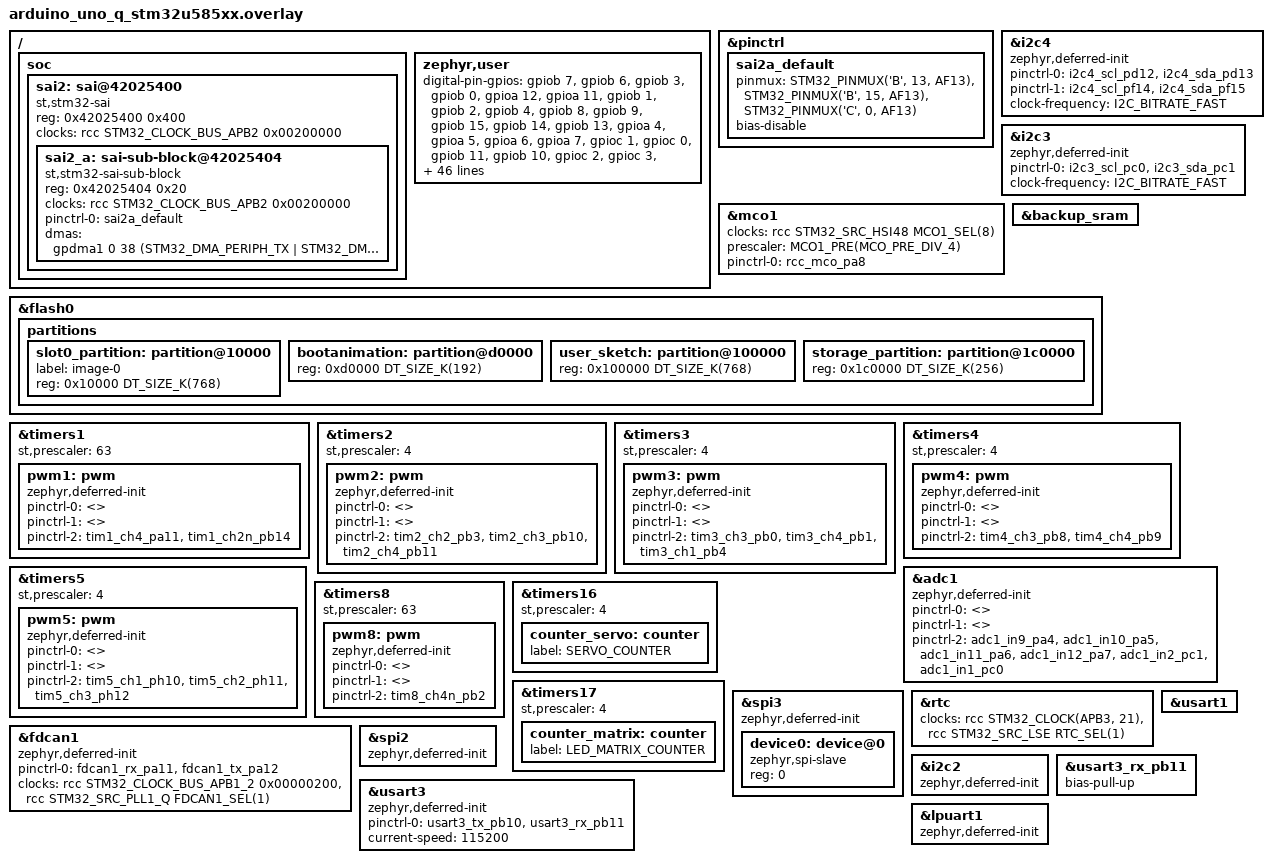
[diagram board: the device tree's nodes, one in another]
/*
 * Copyright (c) Arduino s.r.l. and/or its affiliated companies
 *
 * SPDX-License-Identifier: Apache-2.0
 */
#include <zephyr/dt-bindings/pwm/stm32_pwm.h>
#include <zephyr/dt-bindings/pinctrl/stm32-pinctrl.h>
#include <zephyr/dt-bindings/dma/stm32_dma.h>

/* Pinmux configuration for STM32U585 SAI2 Block A */
/*
 * BUG FIX (2026-08-21): the 'group1' sub-node below is Linux-devicetree
 * pinctrl convention (grouping multiple pin configs under named sub-groups
 * for things like open-drain-per-group vs push-pull-per-group). Confirmed
 * via a real CI compile failure that Zephyr's STM32 pinctrl binding
 * (dts/bindings/pinctrl/st,stm32-pinctrl.yaml, upstream
 * zephyrproject-rtos/zephyr) does NOT use that convention -- its
 * child-binding requires `pinmux` directly on the state node itself
 * (one level below &pinctrl), not nested inside an intermediate group.
 * Confirmed against every one of the 4260 real pin definitions in
 * hal_stm32's stm32u585aiix-pinctrl.dtsi (zephyrproject-rtos/hal_stm32):
 * zero use `group1`-style nesting anywhere; every single one sets pinmux
 * directly on its named leaf node (e.g. `sai2_sd_a_pb15 { pinmux = ...; };`).
 * The pin ASSIGNMENTS below were never wrong -- confirmed against that
 * same vendor file (sai2_sck_a_pb13, sai2_sd_a_pb15, sai2_fs_a_pc0, all
 * AF13) -- only this node's nesting depth was.
 */
&pinctrl {
	sai2a_default: sai2a_default {
		pinmux = <STM32_PINMUX('B', 13, AF13)>,  /* D13 -> SAI2_SCK_A (BCLK) */
		         <STM32_PINMUX('B', 15, AF13)>,  /* D11 -> SAI2_SD_A  (DIN)  */
		         <STM32_PINMUX('C',  0, AF13)>;  /* A5  -> SAI2_FS_A  (LRC)  */
		bias-disable;
	};
};

/* Define SAI2 and SAI2 Block A under /soc */
/ {
	soc {
		sai2: sai@42025400 {
			compatible = "st,stm32-sai";
			reg = <0x42025400 0x400>;
			clocks = <&rcc STM32_CLOCK_BUS_APB2 0x00200000>;
			status = "okay";
			#address-cells = <1>;
			#size-cells = <0>;

			sai2_a: sai-sub-block@42025404 {
				compatible = "st,stm32-sai-sub-block";
				reg = <0x42025404 0x20>;
				clocks = <&rcc STM32_CLOCK_BUS_APB2 0x00200000>;
				status = "okay";
				pinctrl-0 = <&sai2a_default>;
				pinctrl-names = "default";
				/*
				 * BUG FIX (2026-08-21): dmas/dma-names are both
				 * `required: true` per dts/bindings/i2s/st,stm32-sai.yaml's
				 * child-binding (upstream zephyrproject-rtos/zephyr) --
				 * confirmed via the SAME CI compile that caught the
				 * group1 nesting bug above, once that first error was
				 * fixed and this one surfaced next.
				 *
				 * Request line 38 (SAI2_A) confirmed directly from ST's
				 * own official HAL driver source, not derived or
				 * guessed: LL_GPDMA1_REQUEST_SAI2_A = 38U, in
				 * STMicroelectronics/stm32u5xx-hal-driver's
				 * Inc/stm32u5xx_ll_dma.h (gated behind #if
				 * defined(SAI2), confirming this chip variant has it).
				 * No board in the public Zephyr tree wires this exact
				 * peripheral (st,stm32-sai-sub-block) to DMA yet, so
				 * there was no existing devicetree example to copy --
				 * this is derived from the vendor's own C header, the
				 * same source Zephyr's own binding documentation
				 * points to ("Refer to your product's Reference
				 * Manual for the list and mapping of available DMA
				 * requests", per dts/bindings/dma/st,stm32u5-dma.yaml's
				 * worked example).
				 *
				 * &gpdma1 confirmed as the correct node label from
				 * this board's own base file
				 * (boards/arduino/uno_q/arduino_uno_q.dts:68,
				 * upstream zephyrproject-rtos/zephyr -- already
				 * enabled there with status = "okay").
				 *
				 * TX only (single channel, single dmas/dma-names
				 * entry): this SAI2_A instance drives the MAX98357A
				 * speaker over I2S -- playback-only, no microphone/
				 * capture path exists on this board, so an RX channel
				 * would configure hardware that is never used.
				 * Channel 0 chosen arbitrarily (this overlay's only
				 * GPDMA1 consumer so far -- no other node currently
				 * claims a channel number to conflict with; channel
				 * numbers on this GPDMA1 instance are not tied to a
				 * specific peripheral, per the binding's own
				 * dma-channels/dma-requests split in
				 * arduino_uno_q_stm32u585xx.dtsi).
				 *
				 * Flag names (STM32_DMA_PERIPH_TX, STM32_DMA_PRIORITY_
				 * MEDIUM) confirmed present in this exact Zephyr
				 * version's own canonical header
				 * (include/zephyr/dt-bindings/dma/stm32_dma.h,
				 * upstream zephyrproject-rtos/zephyr) -- not assumed
				 * to exist from an older-generation board's usage.
				 *
				 * UNVERIFIED BEYOND THIS POINT: the request-number
				 * source (ST's own HAL header) is authoritative for
				 * WHAT the number is, but nothing has yet confirmed
				 * this dmas line actually compiles+links+runs
				 * correctly end-to-end on real hardware -- that is
				 * the next real test, not this comment.
				 */
				dmas = <&gpdma1 0 38 (STM32_DMA_PERIPH_TX | STM32_DMA_PRIORITY_MEDIUM)>;
				dma-names = "tx";
			};
		};
	};
};

&i2c4 {
	status = "okay";
	zephyr,deferred-init;
	pinctrl-0 = <&i2c4_scl_pd12 &i2c4_sda_pd13>;
	pinctrl-1 = <&i2c4_scl_pf14 &i2c4_sda_pf15>;
	pinctrl-names = "default", "sleep";
	clock-frequency = <I2C_BITRATE_FAST>;
};

&i2c3 {
	status = "okay";
	zephyr,deferred-init;
	pinctrl-0 = <&i2c3_scl_pc0 &i2c3_sda_pc1>;
	pinctrl-names = "default"; 
	clock-frequency = <I2C_BITRATE_FAST>;
};

/* clock from HSI48 */
&mco1 {
	status = "okay";
	clocks = <&rcc STM32_SRC_HSI48 MCO1_SEL(8)>;
	prescaler = <MCO1_PRE(MCO_PRE_DIV_4)>;
	pinctrl-0 = <&rcc_mco_pa8>;
	pinctrl-names = "default";
};

&backup_sram {
	status = "okay";
};

/delete-node/ &slot0_partition;
/delete-node/ &slot1_partition;
/delete-node/ &storage_partition;

&flash0 {
	partitions {
		slot0_partition: partition@10000 {
			label = "image-0";
			reg = < 0x10000 DT_SIZE_K(768) >;
		};

		bootanimation: partition@d0000 {
			reg = < 0xd0000 DT_SIZE_K(192) >;
		};

		user_sketch: partition@100000 {
			reg = < 0x100000 DT_SIZE_K(768) >;
		};

		storage_partition: partition@1c0000 {
			reg = < 0x1c0000 DT_SIZE_K(256) >;
		};
	};
};

/* Enable PWM timers */
&timers1 {
	status = "okay";
	st,prescaler = <63>;

	pwm1: pwm {
		status = "okay";
		zephyr,deferred-init;
		pinctrl-0 = <>;
		pinctrl-1 = <>;
		pinctrl-2 = <&tim1_ch4_pa11 &tim1_ch2n_pb14>; /* PB15 & PB13 dedicated to SAI2 */
		pinctrl-names = "default", "sleep", "arduino";
	};
};

&timers2 {
	status = "okay";
	st,prescaler = <4>;

	pwm2: pwm {
		status = "okay";
		zephyr,deferred-init;
		pinctrl-0 = <>;
		pinctrl-1 = <>;
		pinctrl-2 = <&tim2_ch2_pb3 &tim2_ch3_pb10 &tim2_ch4_pb11>;
		pinctrl-names = "default", "sleep", "arduino";
	};
};

&timers3 {
	status = "okay";
	st,prescaler = <4>;

	pwm3: pwm {
		status = "okay";
		zephyr,deferred-init;
		pinctrl-0 = <>;
		pinctrl-1 = <>;
		pinctrl-2 = <&tim3_ch3_pb0 &tim3_ch4_pb1 &tim3_ch1_pb4>;
		pinctrl-names = "default", "sleep", "arduino";
	};
};

&timers4 {
	status = "okay";
	st,prescaler = <4>;

	pwm4: pwm {
		status = "okay";
		zephyr,deferred-init;
		pinctrl-0 = <>;
		pinctrl-1 = <>;
		pinctrl-2 = <&tim4_ch3_pb8 &tim4_ch4_pb9>;
		pinctrl-names = "default", "sleep", "arduino";
	};
};

&timers5 {
	status = "okay";
	st,prescaler = <4>;

	pwm5: pwm {
		status = "okay";
		zephyr,deferred-init;
		pinctrl-0 = <>;
		pinctrl-1 = <>;
		pinctrl-2 = <&tim5_ch1_ph10 &tim5_ch2_ph11 &tim5_ch3_ph12>;
		pinctrl-names = "default", "sleep", "arduino";
	};
};

&adc1 {
	zephyr,deferred-init;
	pinctrl-0 = <>;
	pinctrl-1 = <>;
	pinctrl-2 = <&adc1_in9_pa4 &adc1_in10_pa5 &adc1_in11_pa6 &adc1_in12_pa7 &adc1_in2_pc1 &adc1_in1_pc0>;
	pinctrl-names = "default", "sleep", "arduino";
	status = "okay";
};

&timers8 {
	status = "okay";
	st,prescaler = <63>;

	pwm8: pwm {
		status = "okay";
		zephyr,deferred-init;
		pinctrl-0 = <>;
		pinctrl-1 = <>;
		pinctrl-2 = <&tim8_ch4n_pb2>;
		pinctrl-names = "default", "sleep", "arduino";
	};
};

&timers16 {
	status = "okay";
	st,prescaler = <4>;

	counter_servo: counter {
		status = "okay";
		label = "SERVO_COUNTER";
	};
};

&timers17 {
	status = "okay";
	st,prescaler = <4>;

	counter_matrix: counter {
		status = "okay";
		label = "LED_MATRIX_COUNTER";
	};
};

&spi3 {
	zephyr,deferred-init;
	device0: device@0 {
		compatible = "zephyr,spi-slave";
		reg = <0>;
	};
};

&rtc {
	status = "okay";
	clocks = <&rcc STM32_CLOCK(APB3, 21)>,
	         <&rcc STM32_SRC_LSE RTC_SEL(1)>;
};

&fdcan1 {
	status = "okay";
	zephyr,deferred-init;
	pinctrl-0 = <&fdcan1_rx_pa11 &fdcan1_tx_pa12>;
	pinctrl-names = "default";
	clocks = <&rcc STM32_CLOCK_BUS_APB1_2 0x00000200>,
	         <&rcc STM32_SRC_PLL1_Q FDCAN1_SEL(1)>;
};

&spi2 {
	zephyr,deferred-init;
};

&i2c2 {
	zephyr,deferred-init;
};

&usart1 {
	status = "okay";
};

&usart3_rx_pb11 {
	bias-pull-up;
};

&usart3 {
	status = "okay";
	zephyr,deferred-init;
	pinctrl-0 = <&usart3_tx_pb10 &usart3_rx_pb11>;
	pinctrl-names = "default";
	current-speed = <115200>;
};

&lpuart1 {
	status = "okay";
	zephyr,deferred-init;
};

/ {
	zephyr,user {
		digital-pin-gpios = <&gpiob 7 GPIO_ACTIVE_HIGH>, /* D0 - PB7 */
		                    <&gpiob 6 GPIO_ACTIVE_HIGH>, /* D1 - PB6 */
		                    <&gpiob 3 GPIO_ACTIVE_HIGH>, /* D2 - PB3 */
		                    <&gpiob 0 GPIO_ACTIVE_HIGH>, /* D3 - PB0 */
		                    <&gpioa 12 GPIO_ACTIVE_HIGH>, /* D4 - PA12 */
		                    <&gpioa 11 GPIO_ACTIVE_HIGH>, /* D5 - PA11 */
		                    <&gpiob 1 GPIO_ACTIVE_HIGH>, /* D6 - PB1 */
		                    <&gpiob 2 GPIO_ACTIVE_HIGH>, /* D7 - PB2 */
		                    <&gpiob 4 GPIO_ACTIVE_HIGH>, /* D8 - PB4 */
		                    <&gpiob 8 GPIO_ACTIVE_HIGH>, /* D9 - PB8 */
		                    <&gpiob 9 GPIO_ACTIVE_HIGH>, /* D10 - PB9 */
		                    <&gpiob 15 GPIO_ACTIVE_HIGH>, /* D11 - PB15 */
		                    <&gpiob 14 GPIO_ACTIVE_HIGH>, /* D12 - PB14 */
		                    <&gpiob 13 GPIO_ACTIVE_HIGH>, /* D13 - PB13 */

		                    /* ADCs */
		                    <&gpioa 4 GPIO_ACTIVE_HIGH>, /* A0 - PA4 */
		                    <&gpioa 5 GPIO_ACTIVE_HIGH>, /* A1 - PA5 */
		                    <&gpioa 6 GPIO_ACTIVE_HIGH>, /* A2 - PA6 */
		                    <&gpioa 7 GPIO_ACTIVE_HIGH>, /* A3 - PA7 */
		                    <&gpioc 1 GPIO_ACTIVE_HIGH>, /* A4 - PC1 */
		                    <&gpioc 0 GPIO_ACTIVE_HIGH>, /* A5 - PC0 */

		                    <&gpiob 11 GPIO_ACTIVE_HIGH>,  /* D20 - PB11 */
		                    <&gpiob 10 GPIO_ACTIVE_HIGH>,  /* D21 - PB10 */

		                    <&gpioc 2 GPIO_ACTIVE_HIGH>,        /* JSPI */
		                    <&gpioc 3 GPIO_ACTIVE_HIGH>,
		                    <&gpiod 1 GPIO_ACTIVE_HIGH>,

		                    <&gpioc 6 GPIO_ACTIVE_HIGH>,    /* JMISC */
		                    <&gpiod 2 GPIO_ACTIVE_HIGH>,
		                    <&gpioc 7 GPIO_ACTIVE_HIGH>,
		                    <&gpioe 2 GPIO_ACTIVE_HIGH>,
		                    <&gpioc 8 GPIO_ACTIVE_HIGH>,
		                    <&gpioe 3 GPIO_ACTIVE_HIGH>,
		                    <&gpioc 9 GPIO_ACTIVE_HIGH>,
		                    <&gpioe 5 GPIO_ACTIVE_HIGH>,
		                    <&gpioe 4 GPIO_ACTIVE_HIGH>,
		                    <&gpioe 6 GPIO_ACTIVE_HIGH>,
		                    <&gpioi 4 GPIO_ACTIVE_HIGH>,
		                    <&gpioe 7 GPIO_ACTIVE_HIGH>,
		                    <&gpioi 6 GPIO_ACTIVE_HIGH>,
		                    <&gpioe 8 GPIO_ACTIVE_HIGH>,
		                    <&gpioi 7 GPIO_ACTIVE_HIGH>,
		                    <&gpiof 14 GPIO_ACTIVE_HIGH>,
		                    <&gpiod 9 GPIO_ACTIVE_HIGH>,
		                    <&gpiof 15 GPIO_ACTIVE_HIGH>,
		                    <&gpioi 5 GPIO_ACTIVE_HIGH>,
		                    <&gpioa 3 GPIO_ACTIVE_HIGH>,
		                    <&gpiod 8 GPIO_ACTIVE_HIGH>,
		                    <&gpioa 0 GPIO_ACTIVE_HIGH>,
		                    <&gpioa 8 GPIO_ACTIVE_HIGH>,
		                    <&gpioa 1 GPIO_ACTIVE_HIGH>,
		                    <&gpioa 10 GPIO_ACTIVE_HIGH>,

		                    <&gpioh 10 GPIO_ACTIVE_HIGH>,        /* LEDs */
		                    <&gpioh 11 GPIO_ACTIVE_HIGH>,
		                    <&gpioh 12 GPIO_ACTIVE_HIGH>,
		                    <&gpioh 13 GPIO_ACTIVE_HIGH>,
		                    <&gpioh 14 GPIO_ACTIVE_HIGH>,
		                    <&gpioh 15 GPIO_ACTIVE_HIGH>,

		                    <&gpiof 0 GPIO_ACTIVE_HIGH>,        /* LED matrix */
		                    <&gpiof 1 GPIO_ACTIVE_HIGH>,
		                    <&gpiof 2 GPIO_ACTIVE_HIGH>,
		                    <&gpiof 3 GPIO_ACTIVE_HIGH>,
		                    <&gpiof 4 GPIO_ACTIVE_HIGH>,
		                    <&gpiof 5 GPIO_ACTIVE_HIGH>,
		                    <&gpiof 6 GPIO_ACTIVE_HIGH>,
		                    <&gpiof 7 GPIO_ACTIVE_HIGH>,
		                    <&gpiof 8 GPIO_ACTIVE_HIGH>,
		                    <&gpiof 9 GPIO_ACTIVE_HIGH>,
		                    <&gpiof 10 GPIO_ACTIVE_HIGH>,
		                    <&gpiog 13 GPIO_ACTIVE_HIGH>,       /* Internal SPI RDY */
		                    <&gpioa 2 GPIO_ACTIVE_HIGH>,        /* Analog switch for VREF */
		                    <&gpioh 3 GPIO_ACTIVE_HIGH>;        /* BOOT0 */

		builtin-led-gpios = <&gpioh 10 GPIO_ACTIVE_HIGH>,
		                    <&gpioh 11 GPIO_ACTIVE_HIGH>,
		                    <&gpioh 12 GPIO_ACTIVE_HIGH>,
		                    <&gpioh 13 GPIO_ACTIVE_HIGH>,
		                    <&gpioh 14 GPIO_ACTIVE_HIGH>,
		                    <&gpioh 15 GPIO_ACTIVE_HIGH>;

		pwm-pin-gpios =    <&gpiob 3 0>,    /* D2/PB3 - TIM2_CH2 */
		                    <&gpiob 0 0>,    /* D3/PB0 - TIM3_CH3 */
		                    <&gpioa 11 0>,   /* D5/PA11 - TIM1_CH4 */
		                    <&gpiob 1 0>,    /* D6/PB1 - TIM3_CH4 */
		                    <&gpiob 2 0>,    /* D7/PB2 - TIM8_CH4N */
		                    <&gpiob 4 0>,    /* D8/PB4 - TIM3_CH1 */
		                    <&gpiob 8 0>,    /* D9/PB8 - TIM4_CH3 */
		                    <&gpiob 9 0>,    /* D10/PB9 - TIM4_CH4 */
		                    <&gpiob 14 0>,   /* D12/PB14 - TIM1_CH2N */
		                    <&gpiob 11 0>,   /* D20/PB11 - TIM2_CH4 */
		                    <&gpiob 10 0>,   /* D21/PB10 - TIM2_CH3 */
		                    <&gpioh 10 0>,   /* LED3_R - TIM5_CH1 */
		                    <&gpioh 11 0>,   /* LED3_G - TIM5_CH2 */
		                    <&gpioh 12 0>;   /* LED3_B - TIM5_CH3 */

		adc-pin-gpios =    <&gpioa 4 0>,
		                    <&gpioa 5 0>,
		                    <&gpioa 6 0>,
		                    <&gpioa 7 0>,
		                    <&gpioc 1 0>,
		                    <&gpioc 0 0>;

		arduino,router-serial = <&lpuart1>;
		serials = <&usart1>, <&lpuart1>, <&usart3>;
		cans = <&fdcan1>;
		i2cs = <&i2c2>, <&i2c4>, <&i2c3>;
		spis = <&spi2>, <&spi3>;
		i2ss = <&sai2_a>;

		pwms = <&pwm2 2 PWM_HZ(500) PWM_POLARITY_NORMAL>,   /* D2/PB3 → TIM2_CH2 */
		       <&pwm3 3 PWM_HZ(500) PWM_POLARITY_NORMAL>,   /* D3/PB0 → TIM3_CH3 */
		       <&pwm1 4 PWM_HZ(500) PWM_POLARITY_NORMAL>,   /* D5/PA11 → TIM1_CH4 */
		       <&pwm3 4 PWM_HZ(500) PWM_POLARITY_NORMAL>,   /* D6/PB1 → TIM3_CH4 */
		       <&pwm8 4 PWM_HZ(500) (PWM_POLARITY_NORMAL | STM32_PWM_COMPLEMENTARY)>, /* D7/PB2 → TIM8_CH4N */
		       <&pwm3 1 PWM_HZ(500) PWM_POLARITY_NORMAL>,   /* D8/PB4 → TIM3_CH1 */
		       <&pwm4 3 PWM_HZ(500) PWM_POLARITY_NORMAL>,   /* D9/PB8 → TIM4_CH3 */
		       <&pwm4 4 PWM_HZ(500) PWM_POLARITY_NORMAL>,   /* D10/PB9 → TIM4_CH4 */
		       <&pwm1 2 PWM_HZ(500) (PWM_POLARITY_NORMAL | STM32_PWM_COMPLEMENTARY)>, /* D12/PB14 → TIM1_CH2N */
		       <&pwm2 4 PWM_HZ(500) PWM_POLARITY_NORMAL>,   /* D20/PB11 → TIM2_CH4 */
		       <&pwm2 3 PWM_HZ(500) PWM_POLARITY_NORMAL>,   /* D21/PB10 → TIM2_CH3 */
		       <&pwm5 1 PWM_HZ(500) PWM_POLARITY_INVERTED>,   /* LED3_R/PH10 → TIM5_CH1 */
		       <&pwm5 2 PWM_HZ(500) PWM_POLARITY_INVERTED>,   /* LED3_G/PH11 → TIM5_CH2 */
		       <&pwm5 3 PWM_HZ(500) PWM_POLARITY_INVERTED>;   /* LED3_B/PH12 → TIM5_CH3 */

		control-gpios = <&gpiog 13 GPIO_ACTIVE_HIGH>;
		analog-switch-gpios = <&gpioa 2 GPIO_ACTIVE_HIGH>;

		io-channels =   <&adc1 9>,
		                <&adc1 10>,
		                <&adc1 11>,
		                <&adc1 12>,
		                <&adc1 2>,
		                <&adc1 1>;

		dac-pin-gpios = <&gpioa 4 0>,
		                <&gpioa 5 0>;

		dac = <&dac1>;
		dac-channels = <1>, <2>;
		dac-resolution = <12>;
	};
};
